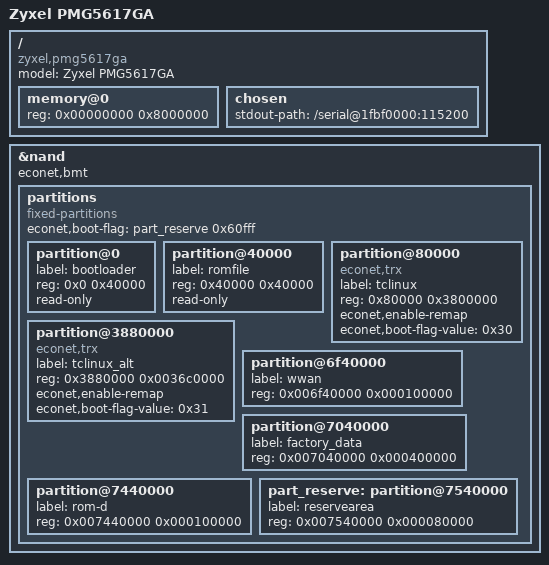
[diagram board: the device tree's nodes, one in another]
// SPDX-License-Identifier: (GPL-2.0-only OR BSD-2-Clause)
/dts-v1/;

#include "en751221.dtsi"

/ {
	model = "Zyxel PMG5617GA";
	compatible = "zyxel,pmg5617ga", "econet,en751221";

	memory@0 {
		device_type = "memory";
		reg = <0x00000000 0x8000000>;
	};

	chosen {
		stdout-path = "/serial@1fbf0000:115200";
	};
};

&nand {
	status = "okay";
	econet,bmt;

	partitions {
		compatible = "fixed-partitions";
		#address-cells = <1>;
		#size-cells = <1>;

		econet,boot-flag = <&part_reserve 0x60fff>;

		partition@0 {
			label = "bootloader";
			reg = <0x0 0x40000>;
			read-only;
		};

		partition@40000 {
			label = "romfile";
			reg = <0x40000 0x40000>;
			read-only;
		};

		partition@80000 {
			compatible = "econet,trx";
			label = "tclinux";
			reg = <0x80000 0x3800000>;
			econet,enable-remap;
			econet,boot-flag-value = <0x30>;
		};

		partition@3880000 {
			compatible = "econet,trx";
			label = "tclinux_alt";
			reg = <0x3880000 0x0036c0000>;
			econet,enable-remap;
			econet,boot-flag-value = <0x31>;
		};

		partition@6f40000 {
			label = "wwan";
			reg = <0x006f40000 0x000100000>;
		};

		partition@7040000 {
			label = "factory_data";
			reg = <0x007040000 0x000400000>;
		};

		partition@7440000 {
			label = "rom-d";
			reg = <0x007440000 0x000100000>;
		};

		part_reserve: partition@7540000 {
			label = "reservearea";
			reg = <0x007540000 0x000080000>;
		};
	};
};
